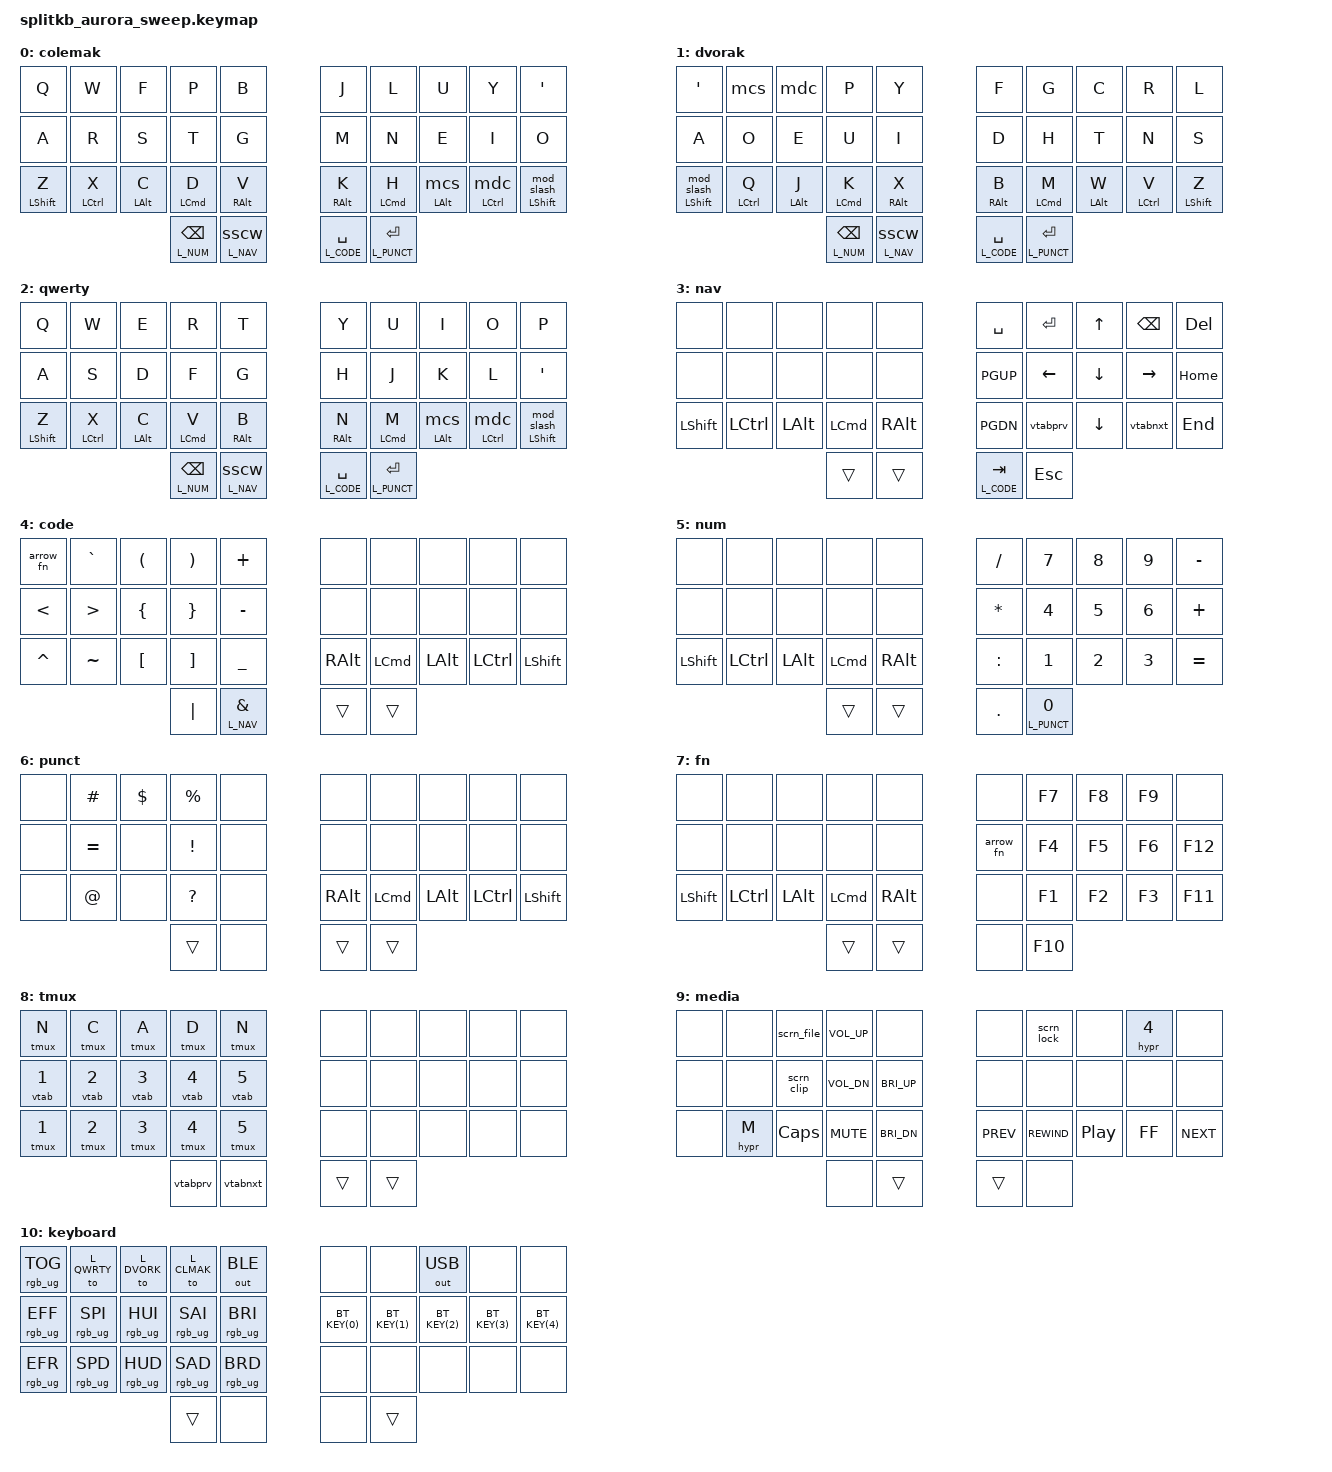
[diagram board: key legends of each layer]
#include <behaviors.dtsi>
#include <dt-bindings/zmk/bt.h>
#include <dt-bindings/zmk/ext_power.h>
#include <dt-bindings/zmk/keys.h>
#include <dt-bindings/zmk/outputs.h>
#include <dt-bindings/zmk/rgb.h>

// Define layer names
#define L_CLMAK 0
#define L_DVORK 1
#define L_QWRTY 2
#define L_NAV   3
#define L_CODE  4
#define L_NUM   5
#define L_PUNCT 6
#define L_FUNC  7
#define L_TMUX  8
#define L_MEDIA 9
#define L_KEYBD 10

// Keyboard layout
//  Q   W   F   P   B       J   L   U   Y   '
//  A   R   S   T   G       M   N   E   I   O
//  Z   X   C   D   V       K   H   ,   .   /
//             bsp sft     spc ret

// Define key positions
#define KQ 0
#define KW 1
#define KF 2
#define KP 3
#define KB 4
#define KJ 5
#define KL 6
#define KU 7
#define KY 8
#define Kquo 9
#define KA 10
#define KR 11
#define KS 12
#define KT 13
#define KG 14
#define KM 15
#define KN 16
#define KE 17
#define KI 18
#define KO 19
#define KZ 20
#define KX 21
#define KC 22
#define KD 23
#define KV 24
#define KK 25
#define KH 26
#define Kcma 27
#define Kdot 28
#define Kslh 29
#define Kbsp 30
#define Ksft 31
#define Kspc 32
#define Kret 33

// Make blank keys more inconspicuous
#define ___ &none

// Shortcuts for punctuation keys
#define OPTcomma &alt_comma LALT 0
#define CTRLdot &ctrl_dot LCTRL 0
#define SHFTslash &shft_slash LSHFT 0

// Macro for bluetooth connections
#define BT_KEY(btnum) &bt_key btnum btnum

// Hardware overrides for this board
&led_strip {
    chain-length = <23>;
};

&nice_view_spi {
    cs-gpios = <&pro_micro 16 GPIO_ACTIVE_HIGH>;
};

&left_encoder1 {
    status = "disabled";
};

&left_encoder2 {
    status = "disabled";
};

&right_encoder1 {
    status = "disabled";
};

&right_encoder2 {
    status = "disabled";
};

// Change default mod-tap settings
&mt {
    flavor = "tap-preferred";
    tapping-term-ms = <200>;
};

/ {
    behaviors {
        alt_comma: mod_alt_comma {
            compatible = "zmk,behavior-hold-tap";
            #binding-cells = <2>;
            flavor = "balanced";
            tapping-term-ms = <200>;
            bindings = <&kp>, <&mcs>;
        };

        bt_key: bluetooth_key {
            compatible = "zmk,behavior-hold-tap";
            #binding-cells = <2>;
            flavor = "tap-preferred";
            tapping-term-ms = <500>;
            bindings = <&bt_sel>, <&bt_clr>;
        };

        bt_magic: bluetooth_magic {
            compatible = "zmk,behavior-tap-dance";
            #binding-cells = <0>;
            bindings = <&bt BT_SEL 4>, <&none>, <&bt BT_CLR>;
        };

        ctrl_dot: mod_ctrl_dot {
            compatible = "zmk,behavior-hold-tap";
            #binding-cells = <2>;
            flavor = "balanced";
            tapping-term-ms = <200>;
            bindings = <&kp>, <&mdc>;
        };

        lsscw: layer_sticky_shift_caps_word {
            compatible = "zmk,behavior-hold-tap";
            #binding-cells = <2>;
            flavor = "balanced";
            tapping-term-ms = <200>;
            bindings = <&mo>, <&sscw>;
        };

        mcs: mod_comma_semi {
            compatible = "zmk,behavior-mod-morph";
            #binding-cells = <0>;
            bindings = <&kp COMMA>, <&kp SEMI>;
            mods = <(MOD_LSFT|MOD_RSFT)>;
        };

        mdc: mod_dot_colon {
            compatible = "zmk,behavior-mod-morph";
            #binding-cells = <0>;
            bindings = <&kp DOT>, <&kp COLON>;
            mods = <(MOD_LSFT|MOD_RSFT)>;
        };

        mod_slash: mod_slash_semi {
            compatible = "zmk,behavior-mod-morph";
            #binding-cells = <0>;
            bindings = <&kp SLASH>, <&kp BACKSLASH>;
            mods = <(MOD_LSFT|MOD_RSFT)>;
        };

        rgb_tog: rgb_toggle {
            compatible = "zmk,behavior-tap-dance";
            #binding-cells = <0>;
            bindings = <&ext_power EP_TOG>, <&rgb_ug RGB_TOG>;
        };

        shft_slash: mod_shft_slash {
            compatible = "zmk,behavior-hold-tap";
            #binding-cells = <2>;
            flavor = "balanced";
            tapping-term-ms = <200>;
            bindings = <&kp>, <&mod_slash>;
        };

        sscw: sticky_shift_caps_word {
            compatible = "zmk,behavior-mod-morph";
            #binding-cells = <0>;
            bindings = <&sk LSHIFT>, <&caps_word>;
            mods = <(MOD_LSFT|MOD_RSFT)>;
        };
    };

    combos {
        compatible = "zmk,combos";
        combo_caps_word {
            layers = <L_CLMAK L_QWRTY>;
            timeout-ms = <50>;
            key-positions = <KZ Kslh>;
            bindings = <&caps_word>;
        };
        combo_cmd_z {
            layers = <L_CLMAK L_QWRTY>;
            timeout-ms = <30>;
            key-positions = <KQ KA>;
            bindings = <&kp LG(Z)>;
        };
        combo_cmd_x {
            layers = <L_CLMAK L_QWRTY>;
            timeout-ms = <30>;
            key-positions = <KW KR>;
            bindings = <&kp LG(X)>;
        };
        combo_cmd_c {
            layers = <L_CLMAK L_QWRTY>;
            timeout-ms = <30>;
            key-positions = <KF KS>;
            bindings = <&kp LG(C)>;
        };
        combo_cmd_d {
            layers = <L_CLMAK L_QWRTY>;
            timeout-ms = <30>;
            key-positions = <KP KT>;
            bindings = <&kp LG(D)>;
        };
        combo_cmd_v {
            layers = <L_CLMAK L_QWRTY>;
            timeout-ms = <30>;
            key-positions = <KB KG>;
            bindings = <&kp LG(V)>;
        };
        combo_ctrl_z {
            layers = <L_CLMAK L_QWRTY>;
            timeout-ms = <30>;
            key-positions = <KA KZ>;
            bindings = <&kp LC(Z)>;
        };
        combo_ctrl_x {
            layers = <L_CLMAK L_QWRTY>;
            timeout-ms = <30>;
            key-positions = <KR KX>;
            bindings = <&kp LC(X)>;
        };
        combo_ctrl_c {
            layers = <L_CLMAK L_QWRTY>;
            timeout-ms = <30>;
            key-positions = <KS KC>;
            bindings = <&kp LC(C)>;
        };
        combo_ctrl_d {
            layers = <L_CLMAK L_QWRTY>;
            timeout-ms = <30>;
            key-positions = <KT KD>;
            bindings = <&kp LC(D)>;
        };
        combo_ctrl_v {
            layers = <L_CLMAK L_QWRTY>;
            timeout-ms = <30>;
            key-positions = <KG KV>;
            bindings = <&kp LC(V)>;
        };
        combo_ctrl_u {
            layers = <L_CLMAK L_QWRTY>;
            timeout-ms = <30>;
            key-positions = <KU KE>;
            bindings = <&kp LC(U)>;
        };
        combo_alt_dot {
            layers = <L_CLMAK L_QWRTY>;
            timeout-ms = <30>;
            key-positions = <KI Kdot>;
            bindings = <&kp LA(DOT)>;
        };
    };

    conditional_layers {
        compatible = "zmk,conditional-layers";
        func_layer {
            if-layers = <L_NAV L_NUM>;
            then-layer = <L_FUNC>;
        };
        tmux_layer {
            if-layers = <L_CODE L_PUNCT>;
            then-layer = <L_TMUX>;
        };
        media_layer {
            if-layers = <L_NAV L_CODE>;
            then-layer = <L_MEDIA>;
        };
        keyboard_layer {
            if-layers = <L_NUM L_PUNCT>;
            then-layer = <L_KEYBD>;
        };
    };

    macros {
        arrow_fn: arrow_function_macro {
            compatible = "zmk,behavior-macro";
            #binding-cells = <0>;
            bindings = <&kp EQUAL &kp GT &kp SPACE>;
        };

        bt_clr: bluetooth_clear_macro {
            compatible = "zmk,behavior-macro-one-param";
            #binding-cells = <1>;
            bindings = <&macro_param_1to2 &bt BT_SEL MACRO_PLACEHOLDER>;
        };

        bt_sel: bluetooth_selection_macro {
            compatible = "zmk,behavior-macro-one-param";
            #binding-cells = <1>;
            bindings =
                <&macro_param_1to2 &bt BT_SEL MACRO_PLACEHOLDER>,
                <&bt BT_CLR>;
        };

        hypr: hyper_mod_macro {
            compatible = "zmk,behavior-macro-one-param";
            #binding-cells = <1>;
            bindings =
                <&macro_press &kp LCMD &kp LALT &kp LCTRL &kp LSHFT>,
                <&macro_param_1to1 &macro_tap &kp MACRO_PLACEHOLDER>,
                <&macro_release &kp LSHFT &kp LCTRL &kp LALT &kp LCMD>;
        };

        meh: meh_mod_macro {
            compatible = "zmk,behavior-macro-one-param";
            #binding-cells = <1>;
            bindings =
                <&macro_press &kp LALT &kp LCTRL &kp LSHFT>,
                <&macro_param_1to1 &macro_tap &kp MACRO_PLACEHOLDER>,
                <&macro_release &kp LSHFT &kp LCTRL &kp LALT>;
        };

        mod_gc: gui_ctrl_mod_macro {
            compatible = "zmk,behavior-macro-one-param";
            #binding-cells = <1>;
            bindings =
                <&macro_press &kp LCMD &kp LCTRL>,
                <&macro_param_1to1 &macro_tap &kp MACRO_PLACEHOLDER>,
                <&macro_release &kp LCTRL &kp LCMD>;
        };

        mod_gcs: gui_ctrl_shft_mod_macro {
            compatible = "zmk,behavior-macro-one-param";
            #binding-cells = <1>;
            bindings =
                <&macro_press &kp LCMD &kp LCTRL &kp LSHFT>,
                <&macro_param_1to1 &macro_tap &kp MACRO_PLACEHOLDER>,
                <&macro_release &kp LSHFT &kp LCTRL &kp LCMD>;
        };

        mod_gs: gui_shft_mod_macro {
            compatible = "zmk,behavior-macro-one-param";
            #binding-cells = <1>;
            bindings =
                <&macro_press &kp LCMD &kp LSHFT>,
                <&macro_param_1to1 &macro_tap &kp MACRO_PLACEHOLDER>,
                <&macro_release &kp LSHFT &kp LCMD>;
        };

        scrn_clip: screen_capture_to_clipboard_macro {
            compatible = "zmk,behavior-macro";
            #binding-cells = <0>;
            bindings = <&mod_gcs N4>;
        };

        scrn_file: screen_capture_to_file_macro {
            compatible = "zmk,behavior-macro";
            #binding-cells = <0>;
            bindings = <&mod_gs N4>;
        };

        scrn_lock: screen_lock_macro {
            compatible = "zmk,behavior-macro";
            #binding-cells = <0>;
            bindings = <&mod_gc Q>;
        };

        tmux: tmux_prefix_macro {
            compatible = "zmk,behavior-macro-one-param";
            #binding-cells = <1>;
            bindings =
                <&macro_tap &kp LC(B)>,
                <&macro_param_1to1 &macro_tap &kp MACRO_PLACEHOLDER>;
        };

        vtab: vim_tab_macro {
            compatible = "zmk,behavior-macro-one-param";
            #binding-cells = <1>;
            bindings =
                <&macro_param_1to1 &macro_tap &kp MACRO_PLACEHOLDER>,
                <&macro_tap &kp G &kp T>;
        };

        vtabnxt: vim_tab_next_macro {
            compatible = "zmk,behavior-macro";
            #binding-cells = <0>;
            bindings = <&macro_tap &kp G &kp T>;
        };

        vtabprv: vim_tab_prv_macro {
            compatible = "zmk,behavior-macro";
            #binding-cells = <0>;
            bindings = <&macro_tap &kp G &kp LS(T)>;
        };
    };

    keymap {
        compatible = "zmk,keymap";

        colemak_layer {
            display-name = "colemak";
            bindings = <
// =====================================================  ================================================
&kp Q       &kp W       &kp F      &kp P      &kp B       &kp J      &kp L      &kp U    &kp Y   &kp SQT
&kp A       &kp R       &kp S      &kp T      &kp G       &kp M      &kp N      &kp E    &kp I   &kp O
&mt LSHFT Z &mt LCTRL X &mt LALT C &mt LCMD D &mt RALT V  &mt RALT K &mt LCMD H OPTcomma CTRLdot SHFTslash
            &lt L_NUM BSPC         &lsscw L_NAV 0         &lt L_CODE SPACE      &lt L_PUNCT RETURN
            >;
        };

        dvorak_layer {
            display-name = "dvorak";
            bindings = <
// =====================================================  ======================================================
&kp SQT   &mcs        &mdc       &kp P      &kp Y       &kp F      &kp G      &kp C      &kp R       &kp L
&kp A     &kp O       &kp E      &kp U      &kp I       &kp D      &kp H      &kp T      &kp N       &kp S
SHFTslash &mt LCTRL Q &mt LALT J &mt LCMD K &mt RALT X  &mt RALT B &mt LCMD M &mt LALT W &mt LCTRL V &mt LSHFT Z
          &lt L_NUM BSPC         &lsscw L_NAV 0         &lt L_CODE SPACE      &lt L_PUNCT RETURN
            >;
        };

        qwerty_layer {
            display-name = "qwerty";
            bindings = <
// =====================================================  =================================================================
&kp Q       &kp W       &kp E      &kp R      &kp T       &kp Y      &kp U      &kp I    &kp O   &kp P
&kp A       &kp S       &kp D      &kp F      &kp G       &kp H      &kp J      &kp K    &kp L   &kp SQT
&mt LSHFT Z &mt LCTRL X &mt LALT C &mt LCMD V &mt RALT B  &mt RALT N &mt LCMD M OPTcomma CTRLdot SHFTslash
            &lt L_NUM BSPC         &lsscw L_NAV 0         &lt L_CODE SPACE      &lt L_PUNCT RETURN
            >;
        };

        nav_layer {
            display-name = "nav";
            bindings = <
// ===========================================  =============================================
___       ___       ___      ___      ___       &kp SPC  &kp RET  &kp UP   &kp BSPC  &kp DEL
___       ___       ___      ___      ___       &kp PGUP &kp LEFT &kp DOWN &kp RIGHT &kp HOME
&kp LSHFT &kp LCTRL &kp LALT &kp LCMD &kp RALT  &kp PGDN &vtabprv &kp DOWN &vtabnxt  &kp END
                             &trans   &trans    &lt L_CODE TAB    &kp ESC
            >;
        };

        code_layer {
            display-name = "code";
            bindings = <
// =============================================  ==============================================
&arrow_fn &kp GRAVE &kp LPAR &kp RPAR  &kp PLUS   ___      ___      ___      ___       ___
&kp LT    &kp GT    &kp LBRC &kp RBRC  &kp MINUS  ___      ___      ___      ___       ___
&kp CARET &kp TILDE &kp LBKT &kp RBKT  &kp UNDER  &kp RALT &kp LCMD &kp LALT &kp LCTRL &kp LSHFT
                    &kp PIPE &lt L_NAV AMPS       &trans   &trans
            >;
        };

        num_layer {
            display-name = "num";
            bindings = <
// ===========================================  ========================================
___       ___       ___      ___      ___       &kp SLASH &kp N7 &kp N8 &kp N9 &kp MINUS
___       ___       ___      ___      ___       &kp STAR  &kp N4 &kp N5 &kp N6 &kp PLUS
&kp LSHFT &kp LCTRL &kp LALT &kp LCMD &kp RALT  &kp COLON &kp N1 &kp N2 &kp N3 &kp EQUAL
                             &trans   &trans    &kp DOT   &lt L_PUNCT N0
            >;
        };

        punct_layer {
            display-name = "punct";
            bindings = <
// ==================================  ==============================================
___ &kp HASH  &kp DLLR  &kp PRCNT ___  ___      ___      ___      ___       ___
___ &kp EQUAL ___       &kp EXCL  ___  ___      ___      ___      ___       ___
___ &kp AT    ___       &kp QMARK ___  &kp RALT &kp LCMD &kp LALT &kp LCTRL &kp LSHFT
                        &trans    ___  &trans   &trans
            >;
        };

        func_layer {
            display-name = "fn";
            bindings = <
// ===========================================  ======================================
___       ___       ___      ___      ___       ___       &kp F7 &kp F8 &kp F9 ___
___       ___       ___      ___      ___       &arrow_fn &kp F4 &kp F5 &kp F6 &kp F12
&kp LSHFT &kp LCTRL &kp LALT &kp LCMD &kp RALT  ___       &kp F1 &kp F2 &kp F3 &kp F11
                             &trans   &trans    ___       &kp F10
            >;
        };

        tmux_layer {
            display-name = "tmux";
            bindings = <
// =========================================  =================================
&tmux N  &tmux C  &tmux A  &tmux D  &tmux N   ___    ___    ___    ___    ___
&vtab N1 &vtab N2 &vtab N3 &vtab N4 &vtab N5  ___    ___    ___    ___    ___
&tmux N1 &tmux N2 &tmux N3 &tmux N4 &tmux N5  ___    ___    ___    ___    ___
                           &vtabprv &vtabnxt  &trans &trans
            >;
        };

        media_layer {
            display-name = "media";
            bindings = <
// =======================================  ============================================================
___   ___     &scrn_file VOL_UP     ___     ___        &scrn_lock   ___              &hypr N4 ___
___   ___     &scrn_clip VOL_DN     BRI_UP  ___        ___          ___              ___      ___
___   &hypr M &kp CAPS   &kp K_MUTE BRI_DN  &kp C_PREV &kp C_REWIND &kp C_PLAY_PAUSE &kp C_FF &kp C_NEXT
                         ___        &trans  &trans     ___
            >;
        };

        keyboard_layer {
            display-name = "keyboard";
            bindings = <
// ============================================================================  ====================================================
&rgb_ug RGB_TOG &to L_QWRTY     &to L_DVORK     &to L_CLMAK     &out OUT_BLE     ___       ___       &out OUT_USB ___       ___
&rgb_ug RGB_EFF &rgb_ug RGB_SPI &rgb_ug RGB_HUI &rgb_ug RGB_SAI &rgb_ug RGB_BRI  BT_KEY(0) BT_KEY(1) BT_KEY(2)    BT_KEY(3) BT_KEY(4)
&rgb_ug RGB_EFR &rgb_ug RGB_SPD &rgb_ug RGB_HUD &rgb_ug RGB_SAD &rgb_ug RGB_BRD  ___       ___       ___          ___       ___
                                                &trans          ___              ___       &trans
            >;
        };

    };
};

// vim: expandtab softtabstop=4 shiftwidth=4 filetype=devicetree
